# PIC32MX370F512L register map
Registers are 32-bit, access not given, reset 0x0 unless marked. A register's access mark holds for its fields unless they carry their own. Offsets are from the block's base; [hi:lo] are bit positions; {n}, {i} and the like mark numbered series; 'fields as' and 'values as' point back to an identical list.

## DMAC3 — DMAC3 peripheral
Base 0xBF8832A0
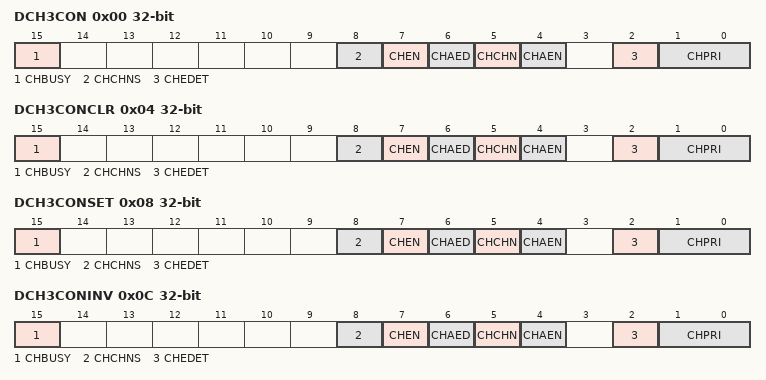
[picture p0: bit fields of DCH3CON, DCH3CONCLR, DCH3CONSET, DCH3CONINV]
0x00 DCH3CON
  [15] CHBUSY, [8] CHCHNS, [7] CHEN, [6] CHAED, [5] CHCHN, [4] CHAEN, [2] CHEDET, [1:0] CHPRI
0x04 DCH3CONCLR
  fields as DCH3CON
0x08 DCH3CONSET
  fields as DCH3CON
0x0C DCH3CONINV
  fields as DCH3CON
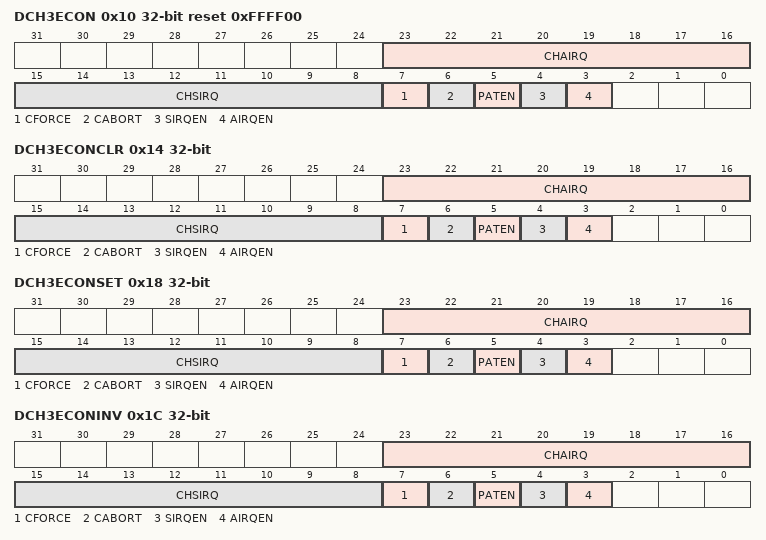
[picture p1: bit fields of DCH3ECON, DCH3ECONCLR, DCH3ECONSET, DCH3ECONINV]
0x10 DCH3ECON reset 0xFFFF00
  [23:16] CHAIRQ, [15:8] CHSIRQ, [7] CFORCE, [6] CABORT, [5] PATEN, [4] SIRQEN, [3] AIRQEN
0x14 DCH3ECONCLR
  fields as DCH3ECON
0x18 DCH3ECONSET
  fields as DCH3ECON
0x1C DCH3ECONINV
  fields as DCH3ECON
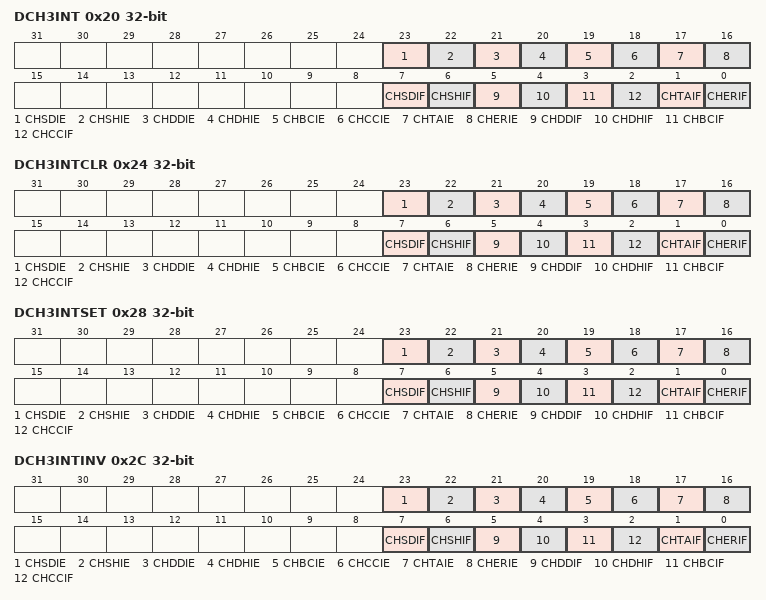
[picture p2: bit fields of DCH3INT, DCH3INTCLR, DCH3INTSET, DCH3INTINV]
0x20 DCH3INT
  [23] CHSDIE, [22] CHSHIE, [21] CHDDIE, [20] CHDHIE, [19] CHBCIE, [18] CHCCIE, [17] CHTAIE, [16] CHERIE, [7] CHSDIF, [6] CHSHIF, [5] CHDDIF, [4] CHDHIF, [3] CHBCIF, [2] CHCCIF, [1] CHTAIF, [0] CHERIF
0x24 DCH3INTCLR
  fields as DCH3INT
0x28 DCH3INTSET
  fields as DCH3INT
0x2C DCH3INTINV
  fields as DCH3INT
0x30 DCH3SSA
0x34 DCH3SSACLR
  [31:0] DCH3SSA
0x38 DCH3SSASET
  [31:0] DCH3SSA
0x3C DCH3SSAINV
  [31:0] DCH3SSA
0x40 DCH3DSA
0x44 DCH3DSACLR
  [31:0] DCH3DSA
0x48 DCH3DSASET
  [31:0] DCH3DSA
0x4C DCH3DSAINV
  [31:0] DCH3DSA
0x50 DCH3SSIZ
  [15:0] CHSSIZ
0x54 DCH3SSIZCLR
  [15:0] CHSSIZ
0x58 DCH3SSIZSET
  [15:0] CHSSIZ
0x5C DCH3SSIZINV
  [15:0] CHSSIZ
0x60 DCH3DSIZ
  [15:0] CHDSIZ
0x64 DCH3DSIZCLR
  [15:0] CHDSIZ
0x68 DCH3DSIZSET
  [15:0] CHDSIZ
0x6C DCH3DSIZINV
  [15:0] CHDSIZ
0x70 DCH3SPTR
  [15:0] CHSPTR
0x74 DCH3SPTRCLR
  [15:0] CHSPTR
0x78 DCH3SPTRSET
  [15:0] CHSPTR
0x7C DCH3SPTRINV
  [15:0] CHSPTR
0x80 DCH3DPTR
  [15:0] CHDPTR
0x84 DCH3DPTRCLR
  [15:0] CHDPTR
0x88 DCH3DPTRSET
  [15:0] CHDPTR
0x8C DCH3DPTRINV
  [15:0] CHDPTR
0x90 DCH3CSIZ
  [15:0] CHCSIZ
0x94 DCH3CSIZCLR
  [15:0] CHCSIZ
0x98 DCH3CSIZSET
  [15:0] CHCSIZ
0x9C DCH3CSIZINV
  [15:0] CHCSIZ
0xA0 DCH3CPTR
  [15:0] CHCPTR
0xA4 DCH3CPTRCLR
  [15:0] CHCPTR
0xA8 DCH3CPTRSET
  [15:0] CHCPTR
0xAC DCH3CPTRINV
  [15:0] CHCPTR
0xB0 DCH3DAT
  [7:0] DCHPDAT
0xB4 DCH3DATCLR
  [7:0] DCHPDAT
0xB8 DCH3DATSET
  [7:0] DCHPDAT
0xBC DCH3DATINV
  [7:0] DCHPDAT

## PCACHE — PCACHE peripheral
Base 0xBF884000
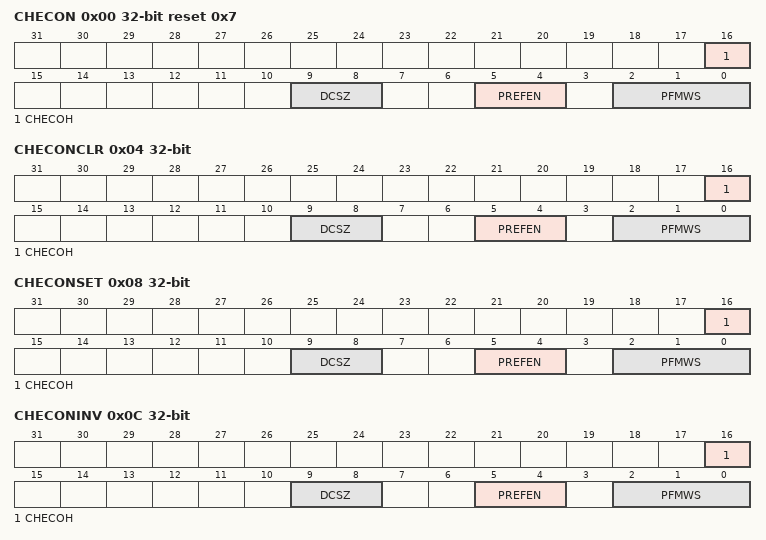
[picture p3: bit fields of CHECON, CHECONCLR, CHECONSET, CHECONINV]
0x00 CHECON reset 0x7
  [16] CHECOH, [9:8] DCSZ, [5:4] PREFEN, [2:0] PFMWS
0x04 CHECONCLR
  [16] CHECOH, [9:8] DCSZ, [5:4] PREFEN, [2:0] PFMWS
0x08 CHECONSET
  [16] CHECOH, [9:8] DCSZ, [5:4] PREFEN, [2:0] PFMWS
0x0C CHECONINV
  [16] CHECOH, [9:8] DCSZ, [5:4] PREFEN, [2:0] PFMWS
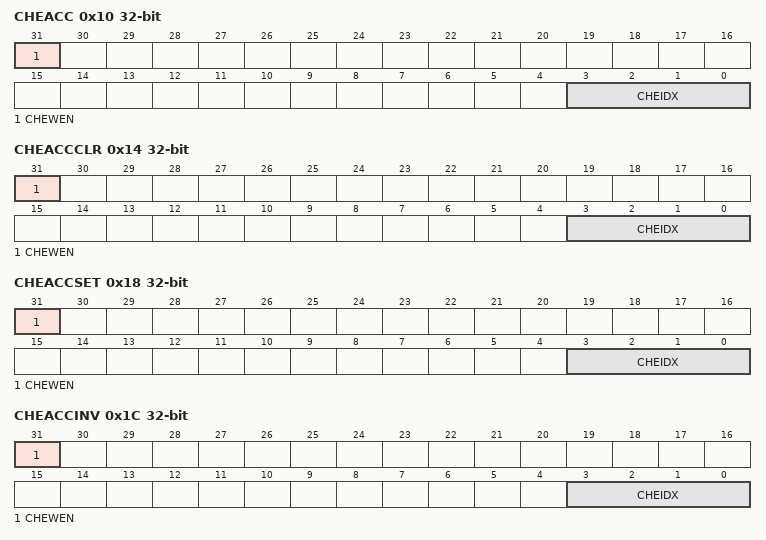
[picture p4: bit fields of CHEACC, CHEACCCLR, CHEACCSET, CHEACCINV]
0x10 CHEACC
  [31] CHEWEN, [3:0] CHEIDX
0x14 CHEACCCLR
  [31] CHEWEN, [3:0] CHEIDX
0x18 CHEACCSET
  [31] CHEWEN, [3:0] CHEIDX
0x1C CHEACCINV
  [31] CHEWEN, [3:0] CHEIDX
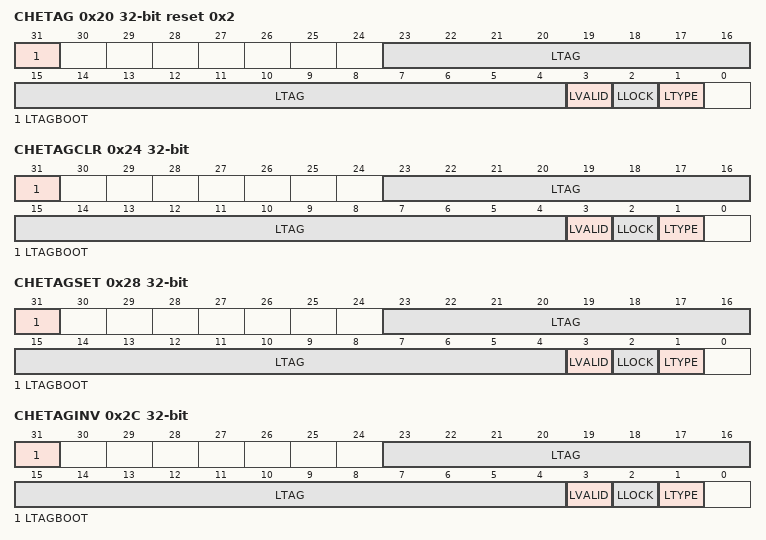
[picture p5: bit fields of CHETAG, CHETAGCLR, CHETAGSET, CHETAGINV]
0x20 CHETAG reset 0x2
  [31] LTAGBOOT, [23:4] LTAG, [3] LVALID, [2] LLOCK, [1] LTYPE
0x24 CHETAGCLR
  [31] LTAGBOOT, [23:4] LTAG, [3] LVALID, [2] LLOCK, [1] LTYPE
0x28 CHETAGSET
  [31] LTAGBOOT, [23:4] LTAG, [3] LVALID, [2] LLOCK, [1] LTYPE
0x2C CHETAGINV
  [31] LTAGBOOT, [23:4] LTAG, [3] LVALID, [2] LLOCK, [1] LTYPE
0x30 CHEMSK
  [15:5] LMASK
0x34 CHEMSKCLR
  [15:5] LMASK
0x38 CHEMSKSET
  [15:5] LMASK
0x3C CHEMSKINV
  [15:5] LMASK
{0x40+0x10*i} CHEW{i} (i=0..3)
0x80 CHELRU
  [24:0] CHELRU
0x90 CHEHIT
0xA0 CHEMIS
0xC0 CHEPFABT

## PORTA — PORTA peripheral
Base 0xBF886000
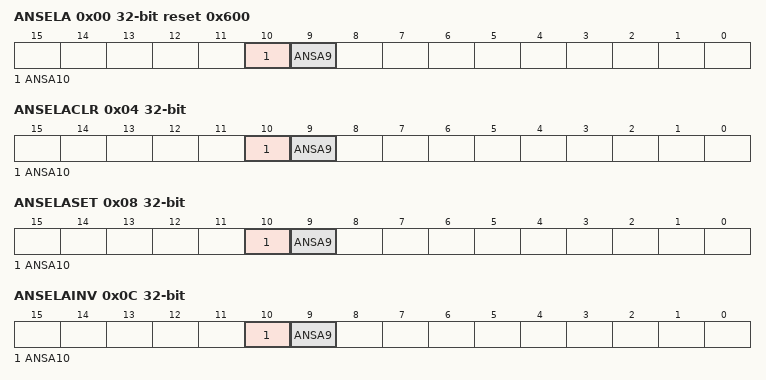
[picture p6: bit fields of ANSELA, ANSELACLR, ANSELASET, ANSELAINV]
0x00 ANSELA reset 0x600
  [10] ANSA10, [9] ANSA9
0x04 ANSELACLR
  [10] ANSA10, [9] ANSA9
0x08 ANSELASET
  [10] ANSA10, [9] ANSA9
0x0C ANSELAINV
  [10] ANSA10, [9] ANSA9
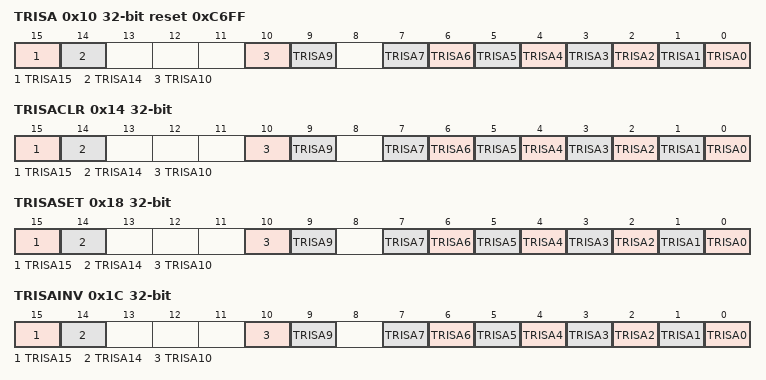
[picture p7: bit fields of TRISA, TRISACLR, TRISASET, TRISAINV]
0x10 TRISA reset 0xC6FF
  [15] TRISA15, [14] TRISA14, [10] TRISA10, [9] TRISA9, [n] TRISA{n} (n=0..7)
0x14 TRISACLR
  fields as TRISA
0x18 TRISASET
  fields as TRISA
0x1C TRISAINV
  fields as TRISA
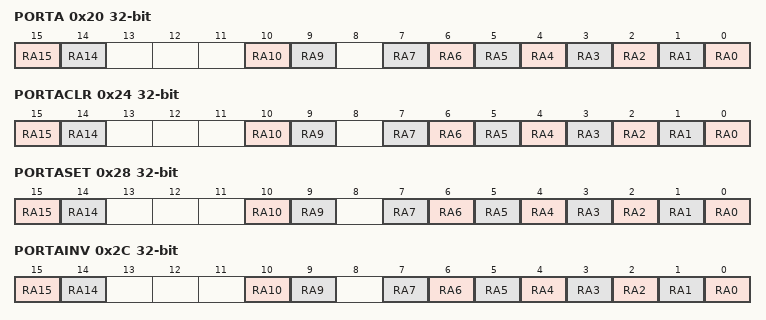
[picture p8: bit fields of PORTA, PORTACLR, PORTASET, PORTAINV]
0x20 PORTA
  [15] RA15, [14] RA14, [10] RA10, [9] RA9, [n] RA{n} (n=0..7)
0x24 PORTACLR
  [15] RA15, [14] RA14, [10] RA10, [9] RA9, [n] RA{n} (n=0..7)
0x28 PORTASET
  [15] RA15, [14] RA14, [10] RA10, [9] RA9, [n] RA{n} (n=0..7)
0x2C PORTAINV
  [15] RA15, [14] RA14, [10] RA10, [9] RA9, [n] RA{n} (n=0..7)
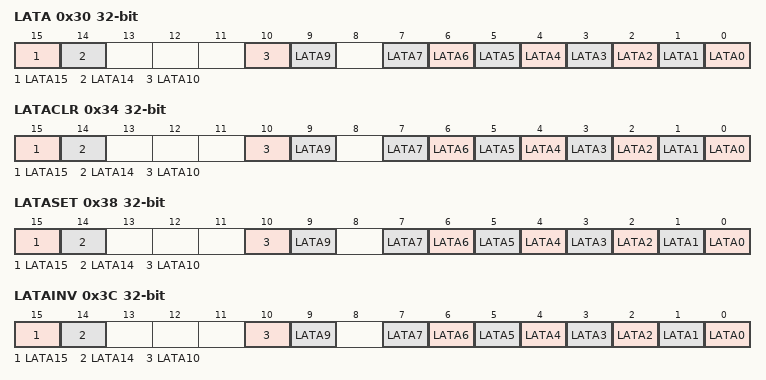
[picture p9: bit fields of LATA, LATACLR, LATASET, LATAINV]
0x30 LATA
  [15] LATA15, [14] LATA14, [10] LATA10, [9] LATA9, [n] LATA{n} (n=0..7)
0x34 LATACLR
  fields as LATA
0x38 LATASET
  fields as LATA
0x3C LATAINV
  fields as LATA
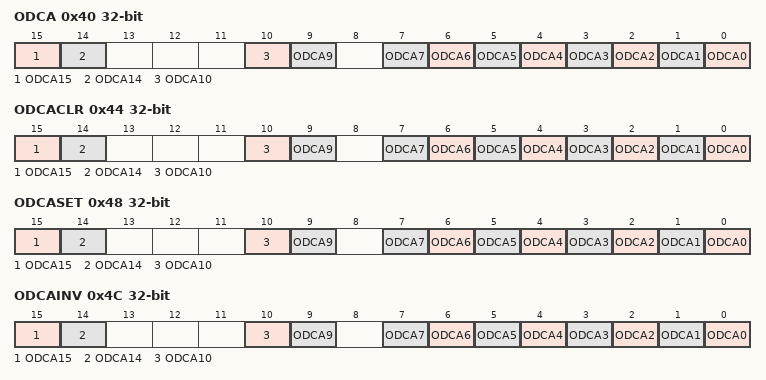
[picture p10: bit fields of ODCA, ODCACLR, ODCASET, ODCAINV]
0x40 ODCA
  [15] ODCA15, [14] ODCA14, [10] ODCA10, [9] ODCA9, [n] ODCA{n} (n=0..7)
0x44 ODCACLR
  fields as ODCA
0x48 ODCASET
  fields as ODCA
0x4C ODCAINV
  fields as ODCA
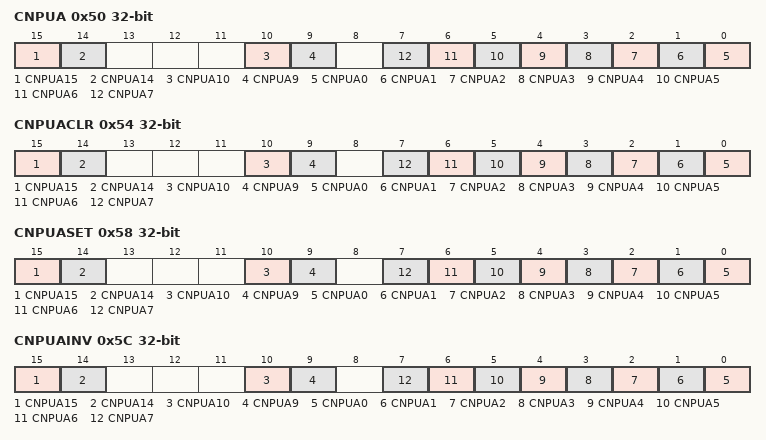
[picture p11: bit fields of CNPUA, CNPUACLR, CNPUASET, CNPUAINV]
0x50 CNPUA
  [15] CNPUA15, [14] CNPUA14, [10] CNPUA10, [9] CNPUA9, [n] CNPUA{n} (n=0..7)
0x54 CNPUACLR
  fields as CNPUA
0x58 CNPUASET
  fields as CNPUA
0x5C CNPUAINV
  fields as CNPUA
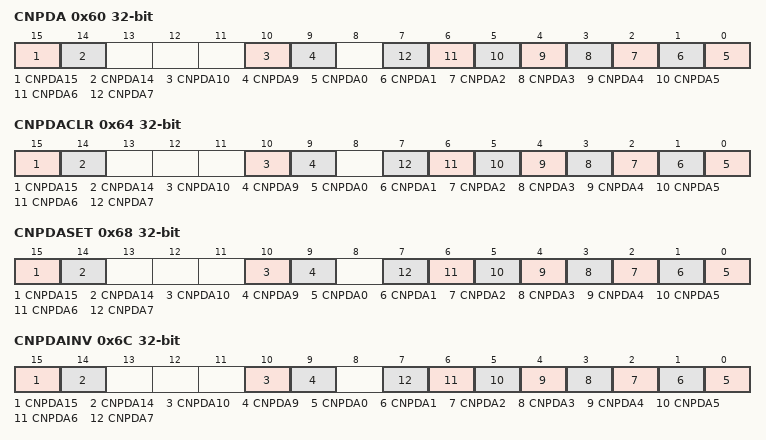
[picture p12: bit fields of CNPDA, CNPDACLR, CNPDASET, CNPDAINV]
0x60 CNPDA
  [15] CNPDA15, [14] CNPDA14, [10] CNPDA10, [9] CNPDA9, [n] CNPDA{n} (n=0..7)
0x64 CNPDACLR
  fields as CNPDA
0x68 CNPDASET
  fields as CNPDA
0x6C CNPDAINV
  fields as CNPDA
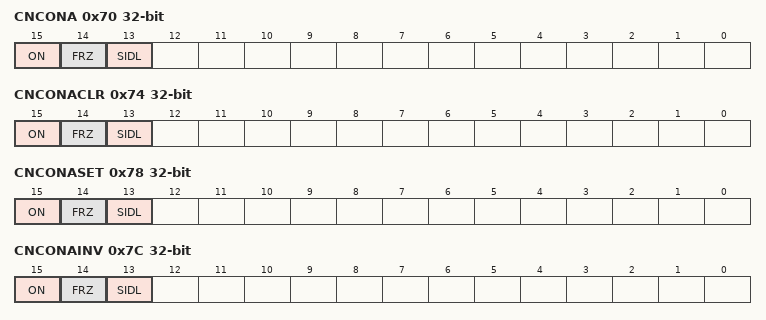
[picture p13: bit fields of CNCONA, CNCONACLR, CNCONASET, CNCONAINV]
0x70 CNCONA
  [15] ON, [14] FRZ, [13] SIDL
0x74 CNCONACLR
  [15] ON, [14] FRZ, [13] SIDL
0x78 CNCONASET
  [15] ON, [14] FRZ, [13] SIDL
0x7C CNCONAINV
  [15] ON, [14] FRZ, [13] SIDL
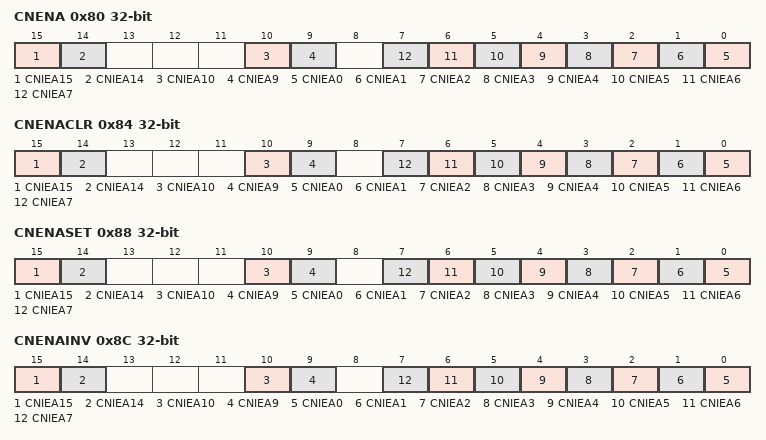
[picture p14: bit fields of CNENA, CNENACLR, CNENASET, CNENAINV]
0x80 CNENA
  [15] CNIEA15, [14] CNIEA14, [10] CNIEA10, [9] CNIEA9, [n] CNIEA{n} (n=0..7)
0x84 CNENACLR
  fields as CNENA
0x88 CNENASET
  fields as CNENA
0x8C CNENAINV
  fields as CNENA
0x90 CNSTATA
  [15] CNSTATA15, [14] CNSTATA14, [10] CNSTATA10, [9] CNSTATA9, [n] CNSTATA{n} (n=0..7)
0x94 CNSTATACLR
  fields as CNSTATA
0x98 CNSTATASET
  fields as CNSTATA
0x9C CNSTATAINV
  fields as CNSTATA
